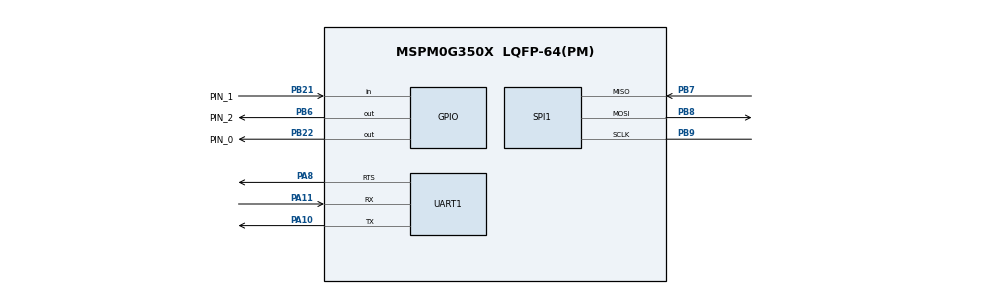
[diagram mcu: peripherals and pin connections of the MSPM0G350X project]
/**
 * @cliArgs --device "MSPM0G350X" --part "Default" --package "LQFP-64(PM)" --product "mspm0_sdk@2.04.00.06"
 * @versions {"tool":"1.21.2+3837"}
 */

/**
 * Import the modules used in this configuration.
 */
const GPIO          = scripting.addModule("/ti/driverlib/GPIO", {}, false);
const GPIO1         = GPIO.addInstance();
const GPIO2         = GPIO.addInstance();
const GPIO3         = GPIO.addInstance();
const I2C           = scripting.addModule("/ti/driverlib/I2C", {}, false);
const I2C1          = I2C.addInstance();
const MATHACL       = scripting.addModule("/ti/driverlib/MATHACL");
const PWM           = scripting.addModule("/ti/driverlib/PWM", {}, false);
const PWM1          = PWM.addInstance();
const SPI           = scripting.addModule("/ti/driverlib/SPI", {}, false);
const SPI1          = SPI.addInstance();
const SYSCTL        = scripting.addModule("/ti/driverlib/SYSCTL");
const TIMER         = scripting.addModule("/ti/driverlib/TIMER", {}, false);
const TIMER1        = TIMER.addInstance();
const TIMER2        = TIMER.addInstance();
const UART          = scripting.addModule("/ti/driverlib/UART", {}, false);
const UART1         = UART.addInstance();
const ProjectConfig = scripting.addModule("/ti/project_config/ProjectConfig");

/**
 * Write custom configuration values to the imported modules.
 */
const divider6       = system.clockTree["PLL_CLK2X_DIV"];
divider6.divideValue = 4;

const divider7       = system.clockTree["PLL_PDIV"];
divider7.divideValue = 4;

const divider9       = system.clockTree["UDIV"];
divider9.divideValue = 2;

const gate7  = system.clockTree["MFCLKGATE"];
gate7.enable = true;

const gate8  = system.clockTree["MFPCLKGATE"];
gate8.enable = true;

const multiplier2         = system.clockTree["PLL_QDIV"];
multiplier2.multiplyValue = 20;

const mux8       = system.clockTree["HSCLKMUX"];
mux8.inputSelect = "HSCLKMUX_SYSPLL2X";

GPIO1.$name                         = "LED";
GPIO1.associatedPins[0].$name       = "PIN_0";
GPIO1.associatedPins[0].pin.$assign = "PB22";

const Board = scripting.addModule("/ti/driverlib/Board", {}, false);

GPIO2.$name                              = "BUTTON";
GPIO2.associatedPins[0].$name            = "PIN_1";
GPIO2.associatedPins[0].direction        = "INPUT";
GPIO2.associatedPins[0].interruptEn      = true;
GPIO2.associatedPins[0].polarity         = "FALL";
GPIO2.associatedPins[0].internalResistor = "PULL_UP";
GPIO2.associatedPins[0].pin.$assign      = "PB21";

GPIO3.$name                         = "SPI_CS";
GPIO3.associatedPins[0].$name       = "PIN_2";
GPIO3.associatedPins[0].pin.$assign = "PB6";

I2C1.$name                        = "I2C_0";
I2C1.basicEnableController        = true;
I2C1.DMAEvent1                    = "CONTROLLER_RXFIFO_TRIGGER";
I2C1.sdaPinConfig.$name           = "ti_driverlib_gpio_GPIOPinGeneric3";
I2C1.sclPinConfig.$name           = "ti_driverlib_gpio_GPIOPinGeneric4";
I2C1.DMA_CHANNEL_EVENT1.$name     = "DMA_CH4";
I2C1.DMA_CHANNEL_EVENT1.srcLength = "BYTE";
I2C1.DMA_CHANNEL_EVENT1.dstLength = "BYTE";

PWM1.$name               = "PWM_0";
PWM1.ccIndex             = [0,1,2,3];
PWM1.PWM_CHANNEL_0.$name = "ti_driverlib_pwm_PWMTimerCC0";
PWM1.PWM_CHANNEL_1.$name = "ti_driverlib_pwm_PWMTimerCC1";
PWM1.ccp0PinConfig.$name = "ti_driverlib_gpio_GPIOPinGeneric12";
PWM1.ccp1PinConfig.$name = "ti_driverlib_gpio_GPIOPinGeneric13";
PWM1.PWM_CHANNEL_2.$name = "ti_driverlib_pwm_PWMTimerCC2";
PWM1.PWM_CHANNEL_3.$name = "ti_driverlib_pwm_PWMTimerCC3";
PWM1.ccp2PinConfig.$name = "ti_driverlib_gpio_GPIOPinGeneric22";
PWM1.ccp3PinConfig.$name = "ti_driverlib_gpio_GPIOPinGeneric23";

SPI1.$name                          = "SPI_0";
SPI1.frameFormat                    = "MOTO3";
SPI1.enabledDMAEvent2Triggers       = "DL_SPI_DMA_INTERRUPT_TX";
SPI1.txFifoThreshold                = "DL_SPI_TX_FIFO_LEVEL_1_4_EMPTY";
SPI1.enabledInterrupts              = ["DMA_DONE_RX","DMA_DONE_TX"];
SPI1.enabledDMAEvent1Triggers       = "DL_SPI_DMA_INTERRUPT_RX";
SPI1.rxFifoThreshold                = "DL_SPI_RX_FIFO_LEVEL_ONE_FRAME";
SPI1.targetBitRate                  = 20000000;
SPI1.peripheral.$assign             = "SPI1";
SPI1.peripheral.sclkPin.$assign     = "PB9";
SPI1.peripheral.mosiPin.$assign     = "PB8";
SPI1.peripheral.misoPin.$assign     = "PB7";
SPI1.sclkPinConfig.$name            = "ti_driverlib_gpio_GPIOPinGeneric0";
SPI1.mosiPinConfig.$name            = "ti_driverlib_gpio_GPIOPinGeneric1";
SPI1.misoPinConfig.$name            = "ti_driverlib_gpio_GPIOPinGeneric2";
SPI1.DMA_CHANNEL_EVENT2.$name       = "DMA_CH2";
SPI1.DMA_CHANNEL_EVENT2.srcLength   = "BYTE";
SPI1.DMA_CHANNEL_EVENT2.dstLength   = "BYTE";
SPI1.DMA_CHANNEL_EVENT2.addressMode = "b2f";
SPI1.DMA_CHANNEL_EVENT1.$name       = "DMA_CH3";
SPI1.DMA_CHANNEL_EVENT1.srcLength   = "BYTE";
SPI1.DMA_CHANNEL_EVENT1.dstLength   = "BYTE";
SPI1.DMA_CHANNEL_EVENT1.addressMode = "f2b";

SYSCTL.forceDefaultClkConfig = true;
SYSCTL.clockTreeEn           = true;

TIMER1.$name              = "TIMER_0";
TIMER1.timerClkDiv        = 4;
TIMER1.timerPeriod        = "1ms";
TIMER1.timerMode          = "PERIODIC";
TIMER1.interrupts         = ["ZERO"];
TIMER1.timerStartTimer    = true;
TIMER1.peripheral.$assign = "TIMG0";

TIMER2.$name              = "TIMER_1";
TIMER2.timerMode          = "ONE_SHOT_UP";
TIMER2.timerClkSrc        = "MFCLK";
TIMER2.timerPeriod        = "1 us";
TIMER2.timerClkDiv        = 4;
TIMER2.peripheral.$assign = "TIMG12";

UART1.$name                                = "UART_0";
UART1.enabledDMATXTriggers                 = "DL_UART_DMA_INTERRUPT_TX";
UART1.enableFIFO                           = true;
UART1.enabledDMARXTriggers                 = "DL_UART_DMA_INTERRUPT_RX";
UART1.rxTimeoutValue                       = 15;
UART1.enabledInterrupts                    = ["RX_TIMEOUT_ERROR"];
UART1.rxFifoThreshold                      = "DL_UART_RX_FIFO_LEVEL_3_4_FULL";
UART1.uartMode                             = "RS485";
UART1.flowControl                          = "RTS";
UART1.setExtDriverSetup                    = 1;
UART1.setExtDriverHold                     = 1;
UART1.targetBaudRate                       = 1000000;
UART1.peripheral.$assign                   = "UART0";
UART1.peripheral.rxPin.$assign             = "PA11";
UART1.peripheral.txPin.$assign             = "PA10";
UART1.peripheral.rtsPin.$assign            = "PA8";
UART1.txPinConfig.$name                    = "ti_driverlib_gpio_GPIOPinGeneric6";
UART1.rxPinConfig.$name                    = "ti_driverlib_gpio_GPIOPinGeneric7";
UART1.DMA_CHANNEL_TX.$name                 = "DMA_CH0";
UART1.DMA_CHANNEL_TX.srcLength             = "BYTE";
UART1.DMA_CHANNEL_TX.dstLength             = "BYTE";
UART1.DMA_CHANNEL_TX.addressMode           = "b2f";
UART1.DMA_CHANNEL_RX.$name                 = "DMA_CH1";
UART1.DMA_CHANNEL_RX.srcLength             = "BYTE";
UART1.DMA_CHANNEL_RX.dstLength             = "BYTE";
UART1.DMA_CHANNEL_RX.configureTransferSize = true;
UART1.DMA_CHANNEL_RX.transferSize          = 1024;
UART1.DMA_CHANNEL_RX.addressMode           = "f2b";
UART1.rtsPinConfig.$name                   = "ti_driverlib_gpio_GPIOPinGeneric5";

ProjectConfig.genLibIQ        = true;
ProjectConfig.genLibIQVersion = "MATHACL";

/**
 * Pinmux solution for unlocked pins/peripherals. This ensures that minor changes to the automatic solver in a future
 * version of the tool will not impact the pinmux you originally saw.  These lines can be completely deleted in order to
 * re-solve from scratch.
 */
Board.peripheral.$suggestSolution                   = "DEBUGSS";
Board.peripheral.swclkPin.$suggestSolution          = "PA20";
Board.peripheral.swdioPin.$suggestSolution          = "PA19";
I2C1.peripheral.$suggestSolution                    = "I2C0";
I2C1.peripheral.sdaPin.$suggestSolution             = "PA28";
I2C1.peripheral.sclPin.$suggestSolution             = "PA31";
I2C1.DMA_CHANNEL_EVENT1.peripheral.$suggestSolution = "DMA_CH4";
PWM1.peripheral.$suggestSolution                    = "TIMA0";
PWM1.peripheral.ccp0Pin.$suggestSolution            = "PA0";
PWM1.peripheral.ccp1Pin.$suggestSolution            = "PA1";
PWM1.peripheral.ccp2Pin.$suggestSolution            = "PA15";
PWM1.peripheral.ccp3Pin.$suggestSolution            = "PA12";
SPI1.DMA_CHANNEL_EVENT2.peripheral.$suggestSolution = "DMA_CH3";
SPI1.DMA_CHANNEL_EVENT1.peripheral.$suggestSolution = "DMA_CH2";
UART1.DMA_CHANNEL_TX.peripheral.$suggestSolution    = "DMA_CH1";
UART1.DMA_CHANNEL_RX.peripheral.$suggestSolution    = "DMA_CH0";
